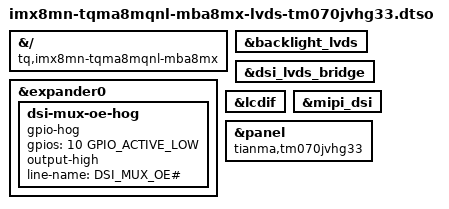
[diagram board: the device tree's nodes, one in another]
// SPDX-License-Identifier: (GPL-2.0-or-later OR MIT)
/*
 * Copyright (c) 2022-2023 TQ-Systems GmbH <linux@ew.tq-group.com>,
 * D-82229 Seefeld, Germany.
 * Author: Alexander Stein
 */

/dts-v1/;
/plugin/;

#include <dt-bindings/gpio/gpio.h>

&{/} {
	compatible = "tq,imx8mn-tqma8mqnl-mba8mx", "tq,imx8mn-tqma8mqnl", "fsl,imx8mn";
};

&backlight_lvds {
	status = "okay";
};

&dsi_lvds_bridge {
	status = "okay";
};

&expander0 {
	dsi-mux-oe-hog {
		gpio-hog;
		gpios = <10 GPIO_ACTIVE_LOW>;
		output-high;
		line-name = "DSI_MUX_OE#";
	};
};

&lcdif {
	status = "okay";
};

&mipi_dsi {
	status = "okay";
};

&panel {
	compatible = "tianma,tm070jvhg33";
	status = "okay";
};
